# SAM9X60 device description
Architecture: ARM926EJS; Family: SAM9; Series: SAM9X
Registers are 32-bit, read-write, no defined reset value unless marked. A register's access mark holds for its fields unless they carry their own. Offsets are from the block's base; [hi:lo] are bit positions; lines under a group give offsets from that group; {n}, {i} and the like mark numbered series; 'fields as' and 'values as' point back to an identical list; <NAME> marks a mode.

## TC — Timer Counter
Instances: TC0 0xF8008000, TC1 0xF800C000
{0x0+0x40*i} TC_CHANNEL[{i}] (i=0..2) group
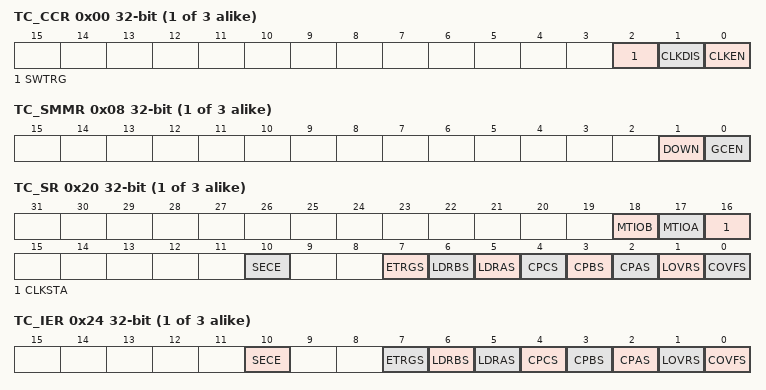
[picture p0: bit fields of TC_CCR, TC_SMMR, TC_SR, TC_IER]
  0x00 TC_CCR wo — Channel Control Register
    [2] SWTRG — Software Trigger Command
    [1] CLKDIS — Counter Clock Disable Command
    [0] CLKEN — Counter Clock Enable Command
  0x04 TC_CMR — Channel Mode Register
    [22:20] SBSMPLR <CAPTURE_MODE> — Loading Edge Subsampling Ratio
      0=ONE (Load a Capture register each selected edge); 1=HALF (Load a Capture register every 2 selected edges); 2=FOURTH (Load a Capture register every 4 selected edges); 3=EIGHTH (Load a Capture register every 8 selected edges); 4=SIXTEENTH (Load a Capture register every 16 selected edges)
    [19:18] LDRB <CAPTURE_MODE> — RB Loading Edge Selection
      0=NONE; 1=RISING (Rising edge of TIOAx); 2=FALLING (Falling edge of TIOAx); 3=EDGE (Each edge of TIOAx)
    [17:16] LDRA <CAPTURE_MODE> — RA Loading Edge Selection
      values as LDRB<CAPTURE_MODE>
    [15] WAVE <CAPTURE_MODE> — Waveform Mode
    [14] CPCTRG <CAPTURE_MODE> — RC Compare Trigger Enable
    [10] ABETRG <CAPTURE_MODE> — TIOAx or TIOBx External Trigger Selection
    [9:8] ETRGEDG <CAPTURE_MODE> — External Trigger Edge Selection
      0=NONE (The clock is not gated by an external signal.); 1=RISING (Rising edge); 2=FALLING (Falling edge); 3=EDGE (Each edge)
    [7] LDBDIS <CAPTURE_MODE> — Counter Clock Disable with RB Loading
    [6] LDBSTOP <CAPTURE_MODE> — Counter Clock Stopped with RB Loading
    [5:4] BURST <CAPTURE_MODE> — Burst Signal Selection
      0=NONE (The clock is not gated by an external signal.); 1=XC0 (XC0 is ANDed with the selected clock.); 2=XC1 (XC1 is ANDed with the selected clock.); 3=XC2 (XC2 is ANDed with the selected clock.)
    [3] CLKI <CAPTURE_MODE> — Clock Invert
    [2:0] TCCLKS <CAPTURE_MODE> — Clock Selection
      0=TIMER_CLOCK1 (Clock selected: internal GCLK [17], GCLK[45] clock signal (from PMC)); 1=TIMER_CLOCK2 (Clock selected: internal div8 clock signal (from PMC)); 2=TIMER_CLOCK3 (Clock selected: internal div32 clock signal (from PMC)); 3=TIMER_CLOCK4 (Clock selected: internal div128 clock signal (from PMC)); 4=TIMER_CLOCK5 (Clock selected: internal MD_SLCK clock signal (from PMC)); 5=XC0 (Clock selected: XC0); 6=XC1 (Clock selected: XC1); 7=XC2 (Clock selected: XC2)
    [31:30] BSWTRG <WAVEFORM_MODE> — Software Trigger Effect on TIOBx
      0=NONE; 1=SET; 2=CLEAR; 3=TOGGLE
    [29:28] BEEVT <WAVEFORM_MODE> — External Event Effect on TIOBx
      0=NONE; 1=SET; 2=CLEAR; 3=TOGGLE
    [27:26] BCPC <WAVEFORM_MODE> — RC Compare Effect on TIOBx
      0=NONE; 1=SET; 2=CLEAR; 3=TOGGLE
    [25:24] BCPB <WAVEFORM_MODE> — RB Compare Effect on TIOBx
      0=NONE; 1=SET; 2=CLEAR; 3=TOGGLE
    [23:22] ASWTRG <WAVEFORM_MODE> — Software Trigger Effect on TIOAx
      0=NONE; 1=SET; 2=CLEAR; 3=TOGGLE
    [21:20] AEEVT <WAVEFORM_MODE> — External Event Effect on TIOAx
      0=NONE; 1=SET; 2=CLEAR; 3=TOGGLE
    [19:18] ACPC <WAVEFORM_MODE> — RC Compare Effect on TIOAx
      0=NONE; 1=SET; 2=CLEAR; 3=TOGGLE
    [17:16] ACPA <WAVEFORM_MODE> — RA Compare Effect on TIOAx
      0=NONE; 1=SET; 2=CLEAR; 3=TOGGLE
    [15] WAVE <WAVEFORM_MODE> — Waveform Mode
    [14:13] WAVSEL <WAVEFORM_MODE> — Waveform Selection
      0=UP (UP mode without automatic trigger on RC Compare); 1=UPDOWN (UPDOWN mode without automatic trigger on RC Compare); 2=UP_RC (UP mode with automatic trigger on RC Compare); 3=UPDOWN_RC (UPDOWN mode with automatic trigger on RC Compare)
    [12] ENETRG <WAVEFORM_MODE> — External Event Trigger Enable
    [11:10] EEVT <WAVEFORM_MODE> — External Event Selection
      0=TIOB; 1=XC0; 2=XC1; 3=XC2
    [9:8] EEVTEDG <WAVEFORM_MODE> — External Event Edge Selection
      0=NONE; 1=RISING (Rising edge); 2=FALLING (Falling edge); 3=EDGE (Each edge)
    [7] CPCDIS <WAVEFORM_MODE> — Counter Clock Disable with RC Compare
    [6] CPCSTOP <WAVEFORM_MODE> — Counter Clock Stopped with RC Compare
    [5:4] BURST <WAVEFORM_MODE> — Burst Signal Selection
      values as BURST<CAPTURE_MODE>
    [3] CLKI <WAVEFORM_MODE> — Clock Invert
    [2:0] TCCLKS <WAVEFORM_MODE> — Clock Selection
      values as TCCLKS<CAPTURE_MODE>
  0x08 TC_SMMR — Stepper Motor Mode Register
    [1] DOWN — Down Count
    [0] GCEN — Gray Count Enable
  0x0C TC_RAB ro — Register AB
    [31:0] RAB — Register A or Register B
  0x10 TC_CV ro — Counter Value
  0x14 TC_RA — Register A
  0x18 TC_RB — Register B
  0x1C TC_RC — Register C
  0x20 TC_SR ro — Interrupt Status Register
    [18] MTIOB — TIOBx Mirror
    [17] MTIOA — TIOAx Mirror
    [16] CLKSTA — Clock Enabling Status
    [10] SECE — Security and/or Safety Event (cleared on read)
    [7] ETRGS — External Trigger Status (cleared on read)
    [6] LDRBS — RB Loading Status (cleared on read)
    [5] LDRAS — RA Loading Status (cleared on read)
    [4] CPCS — RC Compare Status (cleared on read)
    [3] CPBS — RB Compare Status (cleared on read)
    [2] CPAS — RA Compare Status (cleared on read)
    [1] LOVRS — Load Overrun Status (cleared on read)
    [0] COVFS — Counter Overflow Status (cleared on read)
  0x24 TC_IER wo — Interrupt Enable Register
    [10] SECE — Security and/or Safety Event Interrupt Enable
    [7] ETRGS — External Trigger
    [6] LDRBS — RB Loading
    [5] LDRAS — RA Loading
    [4] CPCS — RC Compare
    [3] CPBS — RB Compare
    [2] CPAS — RA Compare
    [1] LOVRS — Load Overrun
    [0] COVFS — Counter Overflow
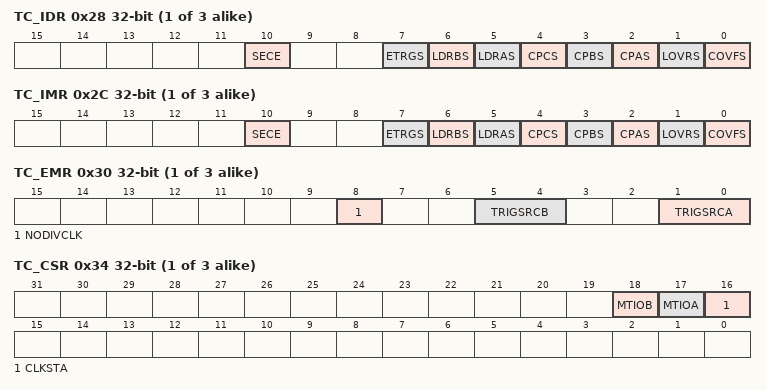
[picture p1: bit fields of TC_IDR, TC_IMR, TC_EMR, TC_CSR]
  0x28 TC_IDR wo — Interrupt Disable Register
    [10] SECE — Security and/or Safety Event Interrupt Disable
    [7] ETRGS — External Trigger
    [6] LDRBS — RB Loading
    [5] LDRAS — RA Loading
    [4] CPCS — RC Compare
    [3] CPBS — RB Compare
    [2] CPAS — RA Compare
    [1] LOVRS — Load Overrun
    [0] COVFS — Counter Overflow
  0x2C TC_IMR ro — Interrupt Mask Register
    [10] SECE — Security and/or Safety Event Interrupt Mask
    [7] ETRGS — External Trigger
    [6] LDRBS — RB Loading
    [5] LDRAS — RA Loading
    [4] CPCS — RC Compare
    [3] CPBS — RB Compare
    [2] CPAS — RA Compare
    [1] LOVRS — Load Overrun
    [0] COVFS — Counter Overflow
  0x30 TC_EMR — Extended Mode Register
    [8] NODIVCLK — No Divided Clock
    [5:4] TRIGSRCB — Trigger Source for Input B
      0=EXTERNAL_TIOBx (The trigger/capture input B is driven by external pin TIOBx); 1=PWMx (The trigger/capture input B is driven internally by the comparator output (see Figure 7-16) of the PWMx.)
    [1:0] TRIGSRCA — Trigger Source for Input A
      0=EXTERNAL_TIOAx (The trigger/capture input A is driven by external pin TIOAx); 1=PWMx (The trigger/capture input A is driven internally by PWMx)
  0x34 TC_CSR ro — Channel Status Register
    [18] MTIOB — TIOBx Mirror
    [17] MTIOA — TIOAx Mirror
    [16] CLKSTA — Clock Enabling Status
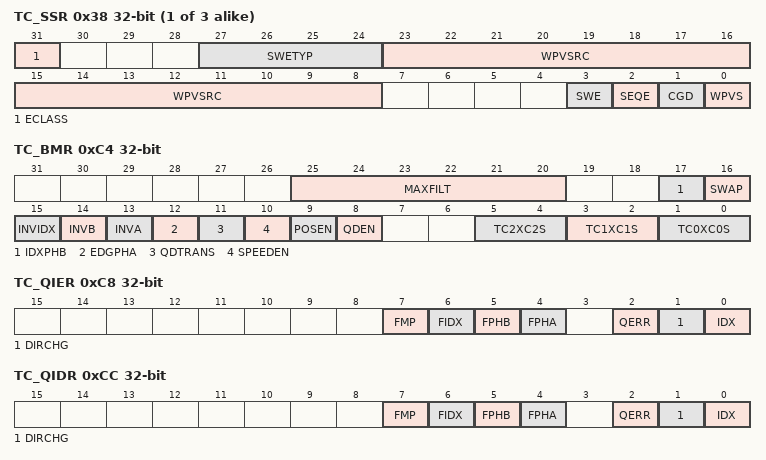
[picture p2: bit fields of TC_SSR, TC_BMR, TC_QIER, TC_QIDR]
  0x38 TC_SSR ro — Safety Status Register
    [31] ECLASS — Software Error Class
      0=WARNING (An abnormal access that does not have any impact.); 1=ERROR (An abnormal access that may have an impact.)
    [27:24] SWETYP — Software Error Type (cleared on read)
      0=READ_WO (TC Channel x is enabled and a write-only register has been read (Warning).); 1=WRITE_RO (TC Channel x is enabled and a write access has been performed on a read-only register (Warning).); 2=UNDEF_RW (Access to an undefined address of the TC (Warning).); 3=W_RARB_CAPT (TC_RAx or TC_RBx are written while channel is enabled and configured in capture mode (Error).)
    [23:8] WPVSRC — Write Protection Violation Source (cleared on read)
    [3] SWE — Software Control Error (cleared on read)
    [2] SEQE — Internal Sequencer Error (cleared on read)
    [1] CGD — Clock Glitch Detected (cleared on read)
    [0] WPVS — Write Protection Violation Status (cleared on read)
0xC0 TC_BCR wo — Block Control Register
  [0] SYNC — Synchro Command
0xC4 TC_BMR — Block Mode Register
  [25:20] MAXFILT — Maximum Filter
  [17] IDXPHB — Index Pin is PHB Pin
  [16] SWAP — Swap PHA and PHB
  [15] INVIDX — Inverted Index
  [14] INVB — Inverted PHB
  [13] INVA — Inverted PHA
  [12] EDGPHA — Edge on PHA Count Mode
  [11] QDTRANS — Quadrature Decoding Transparent
  [10] SPEEDEN — Speed Enabled
  [9] POSEN — Position Enabled
  [8] QDEN — Quadrature Decoder Enabled
  [5:4] TC2XC2S — External Clock Signal 2 Selection
    0=TCLK2 (Signal connected to XC2: TCLK2); 2=TIOA0 (Signal connected to XC2: TIOA0); 3=TIOA1 (Signal connected to XC2: TIOA1)
  [3:2] TC1XC1S — External Clock Signal 1 Selection
    0=TCLK1 (Signal connected to XC1: TCLK1); 2=TIOA0 (Signal connected to XC1: TIOA0); 3=TIOA2 (Signal connected to XC1: TIOA2)
  [1:0] TC0XC0S — External Clock Signal 0 Selection
    0=TCLK0 (Signal connected to XC0: TCLK0); 2=TIOA1 (Signal connected to XC0: TIOA1); 3=TIOA2 (Signal connected to XC0: TIOA2)
0xC8 TC_QIER wo — QDEC Interrupt Enable Register
  [7] FMP — Filtered Missing Pulse
  [6] FIDX — Filtered Index Line
  [5] FPHB — Filtered Phase B Line
  [4] FPHA — Filtered Phase A Line
  [2] QERR — Quadrature Error
  [1] DIRCHG — Direction Change
  [0] IDX — Index
0xCC TC_QIDR wo — QDEC Interrupt Disable Register
  fields as TC_QIER
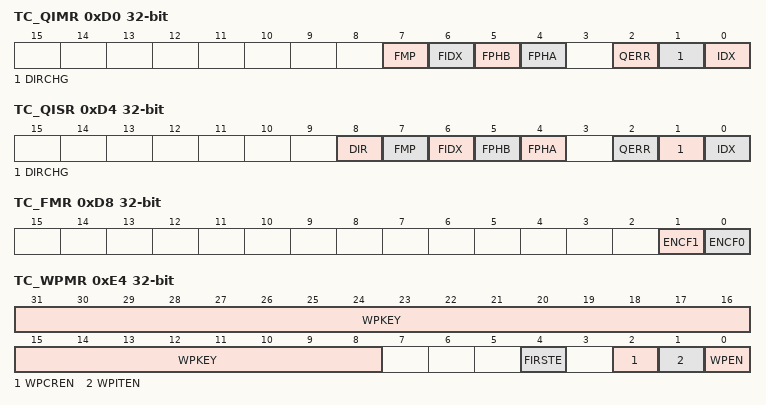
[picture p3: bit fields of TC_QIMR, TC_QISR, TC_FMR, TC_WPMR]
0xD0 TC_QIMR ro — QDEC Interrupt Mask Register
  fields as TC_QIER
0xD4 TC_QISR ro — QDEC Interrupt Status Register
  [8] DIR — Direction
  [7] FMP — Filtered Missing Pulse
  [6] FIDX — Filtered Index Line
  [5] FPHB — Filtered Phase B Line
  [4] FPHA — Filtered Phase A Line
  [2] QERR — Quadrature Error
  [1] DIRCHG — Direction Change
  [0] IDX — Index
0xD8 TC_FMR — Fault Mode Register
  [1] ENCF1 — Enable Compare Fault Channel 1
  [0] ENCF0 — Enable Compare Fault Channel 0
0xDC TC_QSR ro — QDEC Status Register
  [8] DIR — Direction
0xE4 TC_WPMR — Write Protection Mode Register
  [31:8] WPKEY — Write Protection Key
    0x54494D=PASSWD (Writing any other value in this field aborts the write operation of the WPEN bit. Always reads as 0.)
  [4] FIRSTE — First Error Report Enable
  [2] WPCREN — Write Protection Control Enable
  [1] WPITEN — Write Protection Interrupt Enable
  [0] WPEN — Write Protection Enable
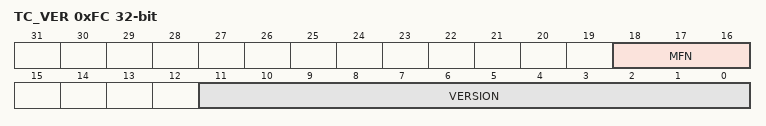
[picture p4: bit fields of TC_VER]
0xFC TC_VER ro — Version Register
  [18:16] MFN — Metal Fix Number
  [11:0] VERSION — Version of the Hardware Module
